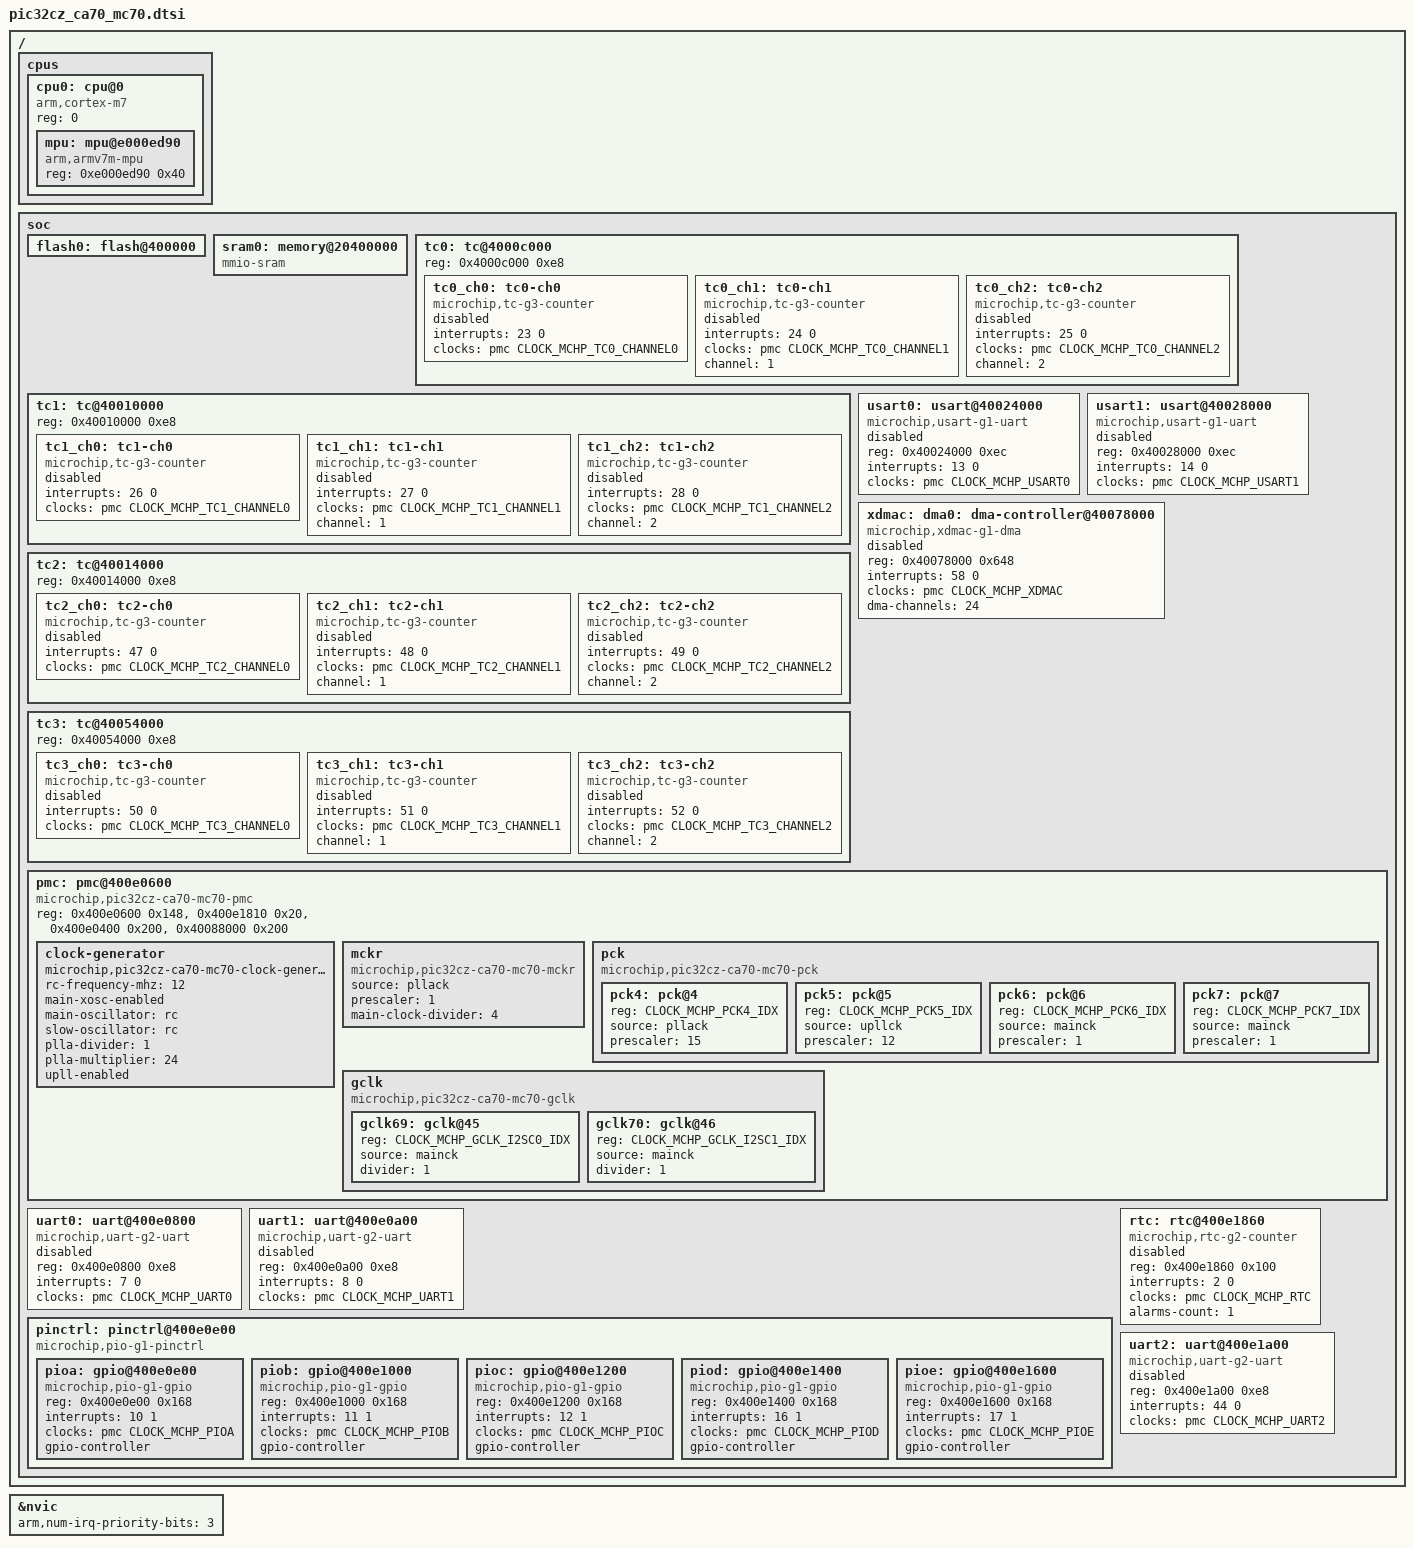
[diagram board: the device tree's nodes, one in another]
/*
 * SPDX-FileCopyrightText: Copyright (c) 2026 Microchip Technology Inc.
 *
 * SPDX-License-Identifier: Apache-2.0
 */

#include <mem.h>
#include <arm/armv7-m.dtsi>
#include <zephyr/dt-bindings/clock/mchp_pic32cz_ca70_mc70_clock.h>
#include <zephyr/dt-bindings/dma/mchp_pic32cz_ca70_mc70_dma.h>

/ {
	cpus {
		#address-cells = <1>;
		#size-cells = <0>;

		cpu0: cpu@0 {
			compatible = "arm,cortex-m7";
			reg = <0>;
			device_type = "cpu";
			#address-cells = <1>;
			#size-cells = <1>;

			mpu: mpu@e000ed90 {
				compatible = "arm,armv7m-mpu";
				reg = <0xe000ed90 0x40>;
			};
		};
	};

	soc {
		flash0: flash@400000 {};

		sram0: memory@20400000 {
			compatible = "mmio-sram";
		};

		tc0: tc@4000c000 {
			reg = <0x4000c000 0xe8>;

			tc0_ch0: tc0-ch0 {
				compatible = "microchip,tc-g3-counter";
				interrupts = <23 0>;
				interrupt-names = "tc0_c0";
				clocks = <&pmc CLOCK_MCHP_TC0_CHANNEL0>;
				clock-names = "mclk";
				#counter-capture-cells = <2>;
				status = "disabled";
			};

			tc0_ch1: tc0-ch1 {
				compatible = "microchip,tc-g3-counter";
				interrupts = <24 0>;
				interrupt-names = "tc0_c1";
				clocks = <&pmc CLOCK_MCHP_TC0_CHANNEL1>;
				clock-names = "mclk";
				channel = <1>;
				#counter-capture-cells = <2>;
				status = "disabled";
			};

			tc0_ch2: tc0-ch2 {
				compatible = "microchip,tc-g3-counter";
				interrupts = <25 0>;
				interrupt-names = "tc0_c2";
				clocks = <&pmc CLOCK_MCHP_TC0_CHANNEL2>;
				clock-names = "mclk";
				channel = <2>;
				#counter-capture-cells = <2>;
				status = "disabled";
			};
		};

		tc1: tc@40010000 {
			reg = <0x40010000 0xe8>;

			tc1_ch0: tc1-ch0 {
				compatible = "microchip,tc-g3-counter";
				interrupts = <26 0>;
				interrupt-names = "tc1_c0";
				clocks = <&pmc CLOCK_MCHP_TC1_CHANNEL0>;
				clock-names = "mclk";
				#counter-capture-cells = <2>;
				status = "disabled";
			};

			tc1_ch1: tc1-ch1 {
				compatible = "microchip,tc-g3-counter";
				interrupts = <27 0>;
				interrupt-names = "tc1_c1";
				clocks = <&pmc CLOCK_MCHP_TC1_CHANNEL1>;
				clock-names = "mclk";
				channel = <1>;
				#counter-capture-cells = <2>;
				status = "disabled";
			};

			tc1_ch2: tc1-ch2 {
				compatible = "microchip,tc-g3-counter";
				interrupts = <28 0>;
				interrupt-names = "tc1_c2";
				clocks = <&pmc CLOCK_MCHP_TC1_CHANNEL2>;
				clock-names = "mclk";
				channel = <2>;
				#counter-capture-cells = <2>;
				status = "disabled";
			};
		};

		tc2: tc@40014000 {
			reg = <0x40014000 0xe8>;

			tc2_ch0: tc2-ch0 {
				compatible = "microchip,tc-g3-counter";
				interrupts = <47 0>;
				interrupt-names = "tc2_c0";
				clocks = <&pmc CLOCK_MCHP_TC2_CHANNEL0>;
				clock-names = "mclk";
				#counter-capture-cells = <2>;
				status = "disabled";
			};

			tc2_ch1: tc2-ch1 {
				compatible = "microchip,tc-g3-counter";
				interrupts = <48 0>;
				interrupt-names = "tc2_c1";
				clocks = <&pmc CLOCK_MCHP_TC2_CHANNEL1>;
				clock-names = "mclk";
				channel = <1>;
				#counter-capture-cells = <2>;
				status = "disabled";
			};

			tc2_ch2: tc2-ch2 {
				compatible = "microchip,tc-g3-counter";
				interrupts = <49 0>;
				interrupt-names = "tc2_c2";
				clocks = <&pmc CLOCK_MCHP_TC2_CHANNEL2>;
				clock-names = "mclk";
				channel = <2>;
				#counter-capture-cells = <2>;
				status = "disabled";
			};
		};

		usart0: usart@40024000 {
			compatible = "microchip,usart-g1-uart";
			reg = <0x40024000 0xec>;
			interrupts = <13 0>;
			interrupt-names = "usart0";
			clocks = <&pmc CLOCK_MCHP_USART0>;
			clock-names = "mclk";
			status = "disabled";
		};

		usart1: usart@40028000 {
			compatible = "microchip,usart-g1-uart";
			reg = <0x40028000 0xec>;
			interrupts = <14 0>;
			interrupt-names = "usart1";
			clocks = <&pmc CLOCK_MCHP_USART1>;
			clock-names = "mclk";
			status = "disabled";
		};

		tc3: tc@40054000 {
			reg = <0x40054000 0xe8>;

			tc3_ch0: tc3-ch0 {
				compatible = "microchip,tc-g3-counter";
				interrupts = <50 0>;
				interrupt-names = "tc3_c0";
				clocks = <&pmc CLOCK_MCHP_TC3_CHANNEL0>;
				clock-names = "mclk";
				#counter-capture-cells = <2>;
				status = "disabled";
			};

			tc3_ch1: tc3-ch1 {
				compatible = "microchip,tc-g3-counter";
				interrupts = <51 0>;
				interrupt-names = "tc3_c1";
				clocks = <&pmc CLOCK_MCHP_TC3_CHANNEL1>;
				clock-names = "mclk";
				channel = <1>;
				#counter-capture-cells = <2>;
				status = "disabled";
			};

			tc3_ch2: tc3-ch2 {
				compatible = "microchip,tc-g3-counter";
				interrupts = <52 0>;
				interrupt-names = "tc3_c2";
				clocks = <&pmc CLOCK_MCHP_TC3_CHANNEL2>;
				clock-names = "mclk";
				channel = <2>;
				#counter-capture-cells = <2>;
				status = "disabled";
			};
		};

		xdmac: dma0: dma-controller@40078000 {
			compatible = "microchip,xdmac-g1-dma";
			reg = <0x40078000 0x648>;
			interrupts = <58 0>;
			interrupt-names = "xdmac";
			clocks = <&pmc CLOCK_MCHP_XDMAC>;
			clock-names = "mclk";
			#dma-cells = <2>;
			dma-channels = <24>;
			status = "disabled";
		};

		pmc: pmc@400e0600 {
			compatible = "microchip,pic32cz-ca70-mc70-pmc";
			reg = <0x400e0600 0x148>, <0x400e1810 0x20>,
			      <0x400e0400 0x200>, <0x40088000 0x200>;
			reg-names = "pmc", "supc", "utmi", "matrix";
			#clock-cells = <1>;
			status = "okay";

			clock-generator {
				compatible = "microchip,pic32cz-ca70-mc70-clock-generator";
				rc-frequency-mhz = <12>;
				main-xosc-enabled;
				main-oscillator = "rc";
				slow-oscillator = "rc";
				plla-divider = <1>;
				plla-multiplier = <24>;
				upll-enabled;
			};

			mckr {
				compatible = "microchip,pic32cz-ca70-mc70-mckr";
				source = "pllack";
				prescaler = <1>;
				main-clock-divider = <4>;
			};

			pck: pck {
				compatible = "microchip,pic32cz-ca70-mc70-pck";

				#address-cells = <1>;
				#size-cells = <0>;

				pck4: pck@4 {
					reg = <CLOCK_MCHP_PCK4_IDX>;
					source = "pllack";
					prescaler = <15>;
				};

				pck5: pck@5 {
					reg = <CLOCK_MCHP_PCK5_IDX>;
					source = "upllck";
					prescaler = <12>;
				};

				pck6: pck@6 {
					reg = <CLOCK_MCHP_PCK6_IDX>;
					source = "mainck";
					prescaler = <1>;
				};

				pck7: pck@7 {
					reg = <CLOCK_MCHP_PCK7_IDX>;
					source = "mainck";
					prescaler = <1>;
				};
			};

			gclk: gclk {
				compatible = "microchip,pic32cz-ca70-mc70-gclk";

				#address-cells = <1>;
				#size-cells = <0>;

				gclk69: gclk@45 {
					reg = <CLOCK_MCHP_GCLK_I2SC0_IDX>;
					source = "mainck";
					divider = <1>;
				};

				gclk70: gclk@46 {
					reg = <CLOCK_MCHP_GCLK_I2SC1_IDX>;
					source = "mainck";
					divider = <1>;
				};
			};
		};

		uart0: uart@400e0800 {
			compatible = "microchip,uart-g2-uart";
			reg = <0x400e0800 0xe8>;
			interrupts = <7 0>;
			interrupt-names = "uart0";
			clocks = <&pmc CLOCK_MCHP_UART0>;
			clock-names = "mclk";
			status = "disabled";
		};

		uart1: uart@400e0a00 {
			compatible = "microchip,uart-g2-uart";
			reg = <0x400e0a00 0xe8>;
			interrupts = <8 0>;
			interrupt-names = "uart1";
			clocks = <&pmc CLOCK_MCHP_UART1>;
			clock-names = "mclk";
			status = "disabled";
		};

		pinctrl: pinctrl@400e0e00 {
			compatible = "microchip,pio-g1-pinctrl";
			ranges = <0x400e0e00 0x400e0e00 0xa00>;
			#address-cells = <1>;
			#size-cells = <1>;

			pioa: gpio@400e0e00 {
				compatible = "microchip,pio-g1-gpio";
				reg = <0x400e0e00 0x168>;
				interrupts = <10 1>;
				interrupt-names = "pioa";
				clocks = <&pmc CLOCK_MCHP_PIOA>;
				clock-names = "mclk";
				gpio-controller;
				#gpio-cells = <2>;
			};

			piob: gpio@400e1000 {
				compatible = "microchip,pio-g1-gpio";
				reg = <0x400e1000 0x168>;
				interrupts = <11 1>;
				interrupt-names = "piob";
				clocks = <&pmc CLOCK_MCHP_PIOB>;
				clock-names = "mclk";
				gpio-controller;
				#gpio-cells = <2>;
			};

			pioc: gpio@400e1200 {
				compatible = "microchip,pio-g1-gpio";
				reg = <0x400e1200 0x168>;
				interrupts = <12 1>;
				interrupt-names = "pioc";
				clocks = <&pmc CLOCK_MCHP_PIOC>;
				clock-names = "mclk";
				gpio-controller;
				#gpio-cells = <2>;
			};

			piod: gpio@400e1400 {
				compatible = "microchip,pio-g1-gpio";
				reg = <0x400e1400 0x168>;
				interrupts = <16 1>;
				interrupt-names = "piod";
				clocks = <&pmc CLOCK_MCHP_PIOD>;
				clock-names = "mclk";
				gpio-controller;
				#gpio-cells = <2>;
			};

			pioe: gpio@400e1600 {
				compatible = "microchip,pio-g1-gpio";
				reg = <0x400e1600 0x168>;
				interrupts = <17 1>;
				interrupt-names = "pioe";
				clocks = <&pmc CLOCK_MCHP_PIOE>;
				clock-names = "mclk";
				gpio-controller;
				#gpio-cells = <2>;
			};
		};

		rtc: rtc@400e1860 {
			compatible = "microchip,rtc-g2-counter";
			reg = <0x400e1860 0x100>;
			interrupts = <2 0>;
			interrupt-names = "rtc";
			clocks = <&pmc CLOCK_MCHP_RTC>;
			clock-names = "mclk";
			alarms-count = <1>;
			status = "disabled";
		};

		uart2: uart@400e1a00 {
			compatible = "microchip,uart-g2-uart";
			reg = <0x400e1a00 0xe8>;
			interrupts = <44 0>;
			interrupt-names = "uart2";
			clocks = <&pmc CLOCK_MCHP_UART2>;
			clock-names = "mclk";
			status = "disabled";
		};
	};
};

&nvic {
	arm,num-irq-priority-bits = <3>;
};
